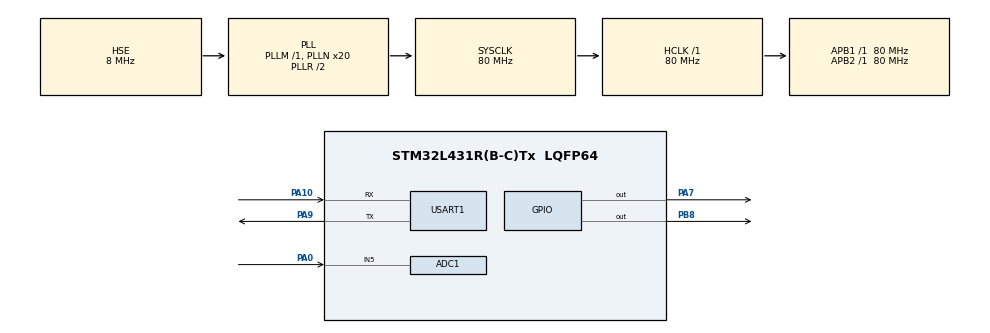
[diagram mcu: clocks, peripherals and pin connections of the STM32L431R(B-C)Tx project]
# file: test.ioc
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ADC1.Channel-0\#ChannelRegularConversion=ADC_CHANNEL_5
ADC1.ContinuousConvMode=ENABLE
ADC1.DMAContinuousRequests=ENABLE
ADC1.EOCSelection=ADC_EOC_SEQ_CONV
ADC1.NbrOfConversionFlag=1
ADC1.OffsetNumber-0\#ChannelRegularConversion=ADC_OFFSET_NONE
ADC1.Rank-0\#ChannelRegularConversion=1
ADC1.SamplingTime-0\#ChannelRegularConversion=ADC_SAMPLETIME_2CYCLES_5
ADC1.master=1
Dma.ADC1.0.Direction=DMA_PERIPH_TO_MEMORY
Dma.ADC1.0.Instance=DMA1_Channel1
Dma.ADC1.0.MemDataAlignment=DMA_MDATAALIGN_WORD
Dma.ADC1.0.MemInc=DMA_MINC_ENABLE
Dma.ADC1.0.Mode=DMA_CIRCULAR
Dma.ADC1.0.PeriphDataAlignment=DMA_PDATAALIGN_WORD
Dma.ADC1.0.PeriphInc=DMA_PINC_DISABLE
Dma.ADC1.0.Priority=DMA_PRIORITY_LOW
Dma.Request0=ADC1
Mcu.Family=STM32L4
Mcu.Name=STM32L431R(B-C)Tx
Mcu.Package=LQFP64
NVIC.DMA1_Channel1_IRQn=true\:0\:0\:false\:false\:true\:false\:true
NVIC.PriorityGroup=NVIC_PRIORITYGROUP_4
PA0.Signal=ADCx_IN5
PA10.Mode=Asynchronous
PA10.Signal=USART1_RX
PA7.Signal=GPIO_Output
PA9.Mode=Asynchronous
PA9.Signal=USART1_TX
PB8.Signal=GPIO_Output
PH0-OSC_IN\ (PH0).Mode=HSE-External-Oscillator
PH0-OSC_IN\ (PH0).Signal=RCC_OSC_IN
PH1-OSC_OUT\ (PH1).Mode=HSE-External-Oscillator
PH1-OSC_OUT\ (PH1).Signal=RCC_OSC_OUT
ProjectManager.HeapSize=0x200
ProjectManager.StackSize=0x400
ProjectManager.TargetToolchain=MDK-ARM V5.27
RCC.ADCFreq_Value=32000000
RCC.AHBFreq_Value=80000000
RCC.APB1Freq_Value=80000000
RCC.APB1TimFreq_Value=80000000
RCC.APB2Freq_Value=80000000
RCC.APB2TimFreq_Value=80000000
RCC.CortexFreq_Value=80000000
RCC.HCLKFreq_Value=80000000
RCC.HSE_VALUE=8000000
RCC.HSI48_VALUE=48000000
RCC.HSI_VALUE=16000000
RCC.LSE_VALUE=32768
RCC.MSI_VALUE=4000000
RCC.PLLN=20
RCC.PLLSourceVirtual=RCC_PLLSOURCE_HSE
RCC.SYSCLKFreq_VALUE=80000000
RCC.SYSCLKSource=RCC_SYSCLKSOURCE_PLLCLK
RCC.VCOOutputFreq_Value=160000000
SH.ADCx_IN5.0=ADC1_IN5,IN5-Single-Ended
USART1.VirtualMode-Asynchronous=VM_ASYNC
board=custom

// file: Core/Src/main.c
/* USER CODE BEGIN Header */
/**
  ******************************************************************************
  * @file           : main.c
  * @brief          : Main program body
  ******************************************************************************
  * @attention
  *
  * <h2><center>&copy; Copyright (c) 2021 STMicroelectronics.
  * All rights reserved.</center></h2>
  *
  * This software component is licensed by ST under BSD 3-Clause license,
  * the "License"; You may not use this file except in compliance with the
  * License. You may obtain a copy of the License at:
  *                        opensource.org/licenses/BSD-3-Clause
  *
  ******************************************************************************
  */
/* USER CODE END Header */
#include "main.h"
#include "adc.h"
#include "dma.h"
#include "usart.h"
#include "gpio.h"

void SystemClock_Config(void);

/* USER CODE BEGIN 0 */
uint8_t data[8]="12345678";

uint32_t s_adc_dma_buf[9600]={0};
/* USER CODE END 0 */

int main(void)
{

  /* MCU Configuration--------------------------------------------------------*/

  /* Reset of all peripherals, Initializes the Flash interface and the Systick. */
  HAL_Init();

  /* Configure the system clock */
  SystemClock_Config();

  /* Initialize all configured peripherals */
  MX_GPIO_Init();
  MX_DMA_Init();
  MX_USART1_UART_Init();
  MX_ADC1_Init();
  /* USER CODE BEGIN 2 */

	HAL_ADCEx_Calibration_Start(&hadc1,ADC_SINGLE_ENDED);
	HAL_ADC_Start_DMA(&hadc1,(uint32_t *)s_adc_dma_buf,9600);
  /* USER CODE END 2 */

  /* Infinite loop */
  while (1)
  {

    /* USER CODE BEGIN 3 */

	  HAL_UART_Transmit(&huart1,data, 8,100);
	  HAL_GPIO_WritePin(GPIOA, GPIO_PIN_7, GPIO_PIN_RESET);
	  HAL_GPIO_WritePin(GPIOB, GPIO_PIN_8, GPIO_PIN_RESET);
	  HAL_Delay(500);
	  HAL_GPIO_WritePin(GPIOA, GPIO_PIN_7, GPIO_PIN_SET);
	  HAL_GPIO_WritePin(GPIOB, GPIO_PIN_8, GPIO_PIN_SET);
	  HAL_Delay(500);

  }
  /* USER CODE END 3 */
}

void SystemClock_Config(void)
{
  RCC_OscInitTypeDef RCC_OscInitStruct = {0};
  RCC_ClkInitTypeDef RCC_ClkInitStruct = {0};
  RCC_PeriphCLKInitTypeDef PeriphClkInit = {0};

  /** Initializes the RCC Oscillators according to the specified parameters
  * in the RCC_OscInitTypeDef structure.
  */
  RCC_OscInitStruct.OscillatorType = RCC_OSCILLATORTYPE_HSE;
  RCC_OscInitStruct.HSEState = RCC_HSE_ON;
  RCC_OscInitStruct.PLL.PLLState = RCC_PLL_ON;
  RCC_OscInitStruct.PLL.PLLSource = RCC_PLLSOURCE_HSE;
  RCC_OscInitStruct.PLL.PLLM = 1;
  RCC_OscInitStruct.PLL.PLLN = 20;
  RCC_OscInitStruct.PLL.PLLP = RCC_PLLP_DIV7;
  RCC_OscInitStruct.PLL.PLLQ = RCC_PLLQ_DIV2;
  RCC_OscInitStruct.PLL.PLLR = RCC_PLLR_DIV2;
  if (HAL_RCC_OscConfig(&RCC_OscInitStruct) != HAL_OK)
  {
    Error_Handler();
  }
  /** Initializes the CPU, AHB and APB buses clocks
  */
  RCC_ClkInitStruct.ClockType = RCC_CLOCKTYPE_HCLK|RCC_CLOCKTYPE_SYSCLK
                              |RCC_CLOCKTYPE_PCLK1|RCC_CLOCKTYPE_PCLK2;
  RCC_ClkInitStruct.SYSCLKSource = RCC_SYSCLKSOURCE_PLLCLK;
  RCC_ClkInitStruct.AHBCLKDivider = RCC_SYSCLK_DIV1;
  RCC_ClkInitStruct.APB1CLKDivider = RCC_HCLK_DIV1;
  RCC_ClkInitStruct.APB2CLKDivider = RCC_HCLK_DIV1;

  if (HAL_RCC_ClockConfig(&RCC_ClkInitStruct, FLASH_LATENCY_4) != HAL_OK)
  {
    Error_Handler();
  }
  PeriphClkInit.PeriphClockSelection = RCC_PERIPHCLK_USART1|RCC_PERIPHCLK_ADC;
  PeriphClkInit.Usart1ClockSelection = RCC_USART1CLKSOURCE_PCLK2;
  PeriphClkInit.AdcClockSelection = RCC_ADCCLKSOURCE_PLLSAI1;
  PeriphClkInit.PLLSAI1.PLLSAI1Source = RCC_PLLSOURCE_HSE;
  PeriphClkInit.PLLSAI1.PLLSAI1M = 1;
  PeriphClkInit.PLLSAI1.PLLSAI1N = 8;
  PeriphClkInit.PLLSAI1.PLLSAI1P = RCC_PLLP_DIV7;
  PeriphClkInit.PLLSAI1.PLLSAI1Q = RCC_PLLQ_DIV2;
  PeriphClkInit.PLLSAI1.PLLSAI1R = RCC_PLLR_DIV2;
  PeriphClkInit.PLLSAI1.PLLSAI1ClockOut = RCC_PLLSAI1_ADC1CLK;
  if (HAL_RCCEx_PeriphCLKConfig(&PeriphClkInit) != HAL_OK)
  {
    Error_Handler();
  }
  /** Configure the main internal regulator output voltage
  */
  if (HAL_PWREx_ControlVoltageScaling(PWR_REGULATOR_VOLTAGE_SCALE1) != HAL_OK)
  {
    Error_Handler();
  }
}

void Error_Handler(void)
{
  __disable_irq();
  while (1)
  {
  }
}

/************************ (C) COPYRIGHT STMicroelectronics *****END OF FILE****/
